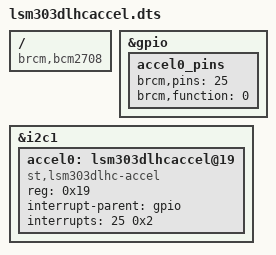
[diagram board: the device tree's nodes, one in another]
////////////////////////////////////////////////////////////////////////////
//
//  This file is part of RTembedded
//
//  Copyright (c) 2015, richards-tech, LLC
//
//  Permission is hereby granted, free of charge, to any person obtaining a copy of
//  this software and associated documentation files (the "Software"), to deal in
//  the Software without restriction, including without limitation the rights to use,
//  copy, modify, merge, publish, distribute, sublicense, and/or sell copies of the
//  Software, and to permit persons to whom the Software is furnished to do so,
//  subject to the following conditions:
//
//  The above copyright notice and this permission notice shall be included in all
//  copies or substantial portions of the Software.
//
//  THE SOFTWARE IS PROVIDED "AS IS", WITHOUT WARRANTY OF ANY KIND, EXPRESS OR IMPLIED,
//  INCLUDING BUT NOT LIMITED TO THE WARRANTIES OF MERCHANTABILITY, FITNESS FOR A
//  PARTICULAR PURPOSE AND NONINFRINGEMENT. IN NO EVENT SHALL THE AUTHORS OR COPYRIGHT
//  HOLDERS BE LIABLE FOR ANY CLAIM, DAMAGES OR OTHER LIABILITY, WHETHER IN AN ACTION
//  OF CONTRACT, TORT OR OTHERWISE, ARISING FROM, OUT OF OR IN CONNECTION WITH THE
//  SOFTWARE OR THE USE OR OTHER DEALINGS IN THE SOFTWARE.

//  Definitions for LSM303DLHC accelerometer
/dts-v1/;
/plugin/;

/ {
    compatible = "brcm,bcm2708";

    fragment@0 {
        target = <&gpio>;
        __overlay__ {
            accel0_pins: accel0_pins {
                brcm,pins = <25>;
                brcm,function = <0>;
            };
        };
    };

    fragment@1 {
        target = <&i2c1>;
        __overlay__ {
            #address-cells = <1>;
            #size-cells = <0>;
            status = "okay";
            accel0: lsm303dlhcaccel@19 {
                compatible = "st,lsm303dlhc-accel";
                reg = <0x19>;
                interrupt-parent = <&gpio>;
                interrupts = <25 0x2>;
                status = "okay";
            };
        };
    };

    __overrides__ {
        interrupt = <&accel0_pins>,"brcm,pins:0",<&accel0>,"interrupts:0";
    };
};
